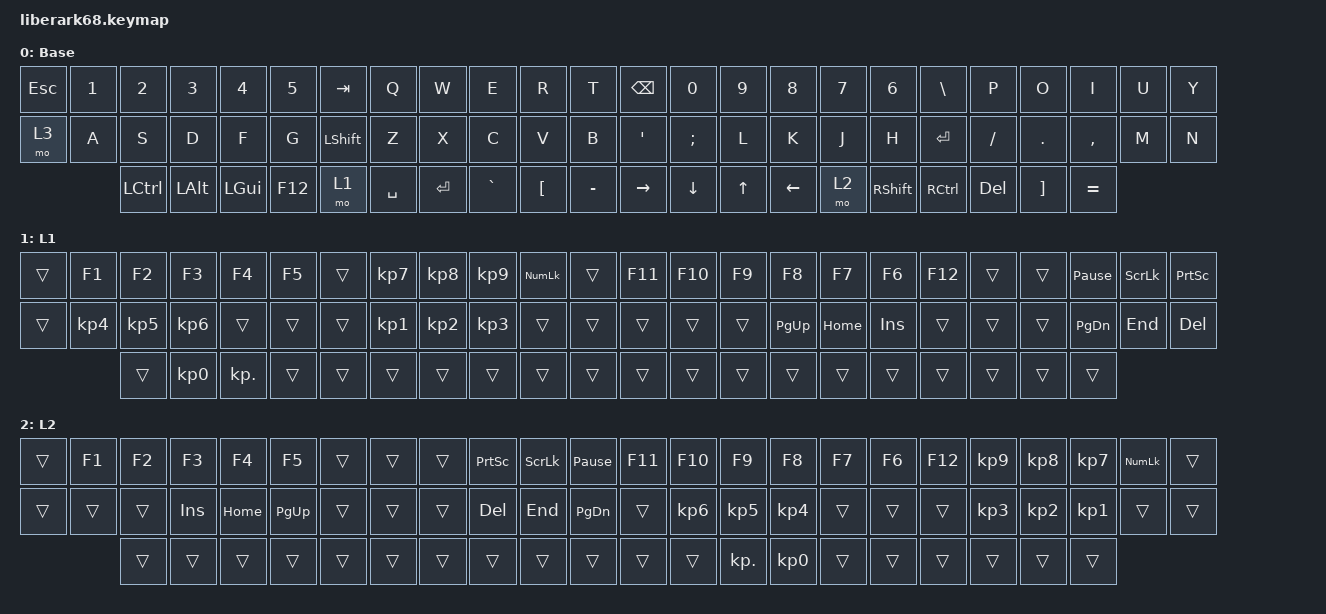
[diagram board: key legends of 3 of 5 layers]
/*
 * LiberArk68 default keymap (dual-fader variant).
 *
 * Bindings order matches the matrix-transform map in liberark68.dtsi:
 *   row 0: L cols 0..11, then R cols 0..11   (24)
 *   row 1: L cols 0..11, then R cols 0..11   (24)
 *   row 2: L cols 0..9,  then R cols 0..9    (20)
 *
 * The faders are analog inputs (not keys), so they don't appear here.
 * Momentary layer keys from the KLE: L outer-mid -> mo 3, L thumb -> mo 1,
 * R thumb -> mo 2. Layers 1 and 2 provide mirrored keypad/navigation layouts;
 * layers 3 and 4 remain placeholder &trans maps.
 */

#include <behaviors.dtsi>
#include <dt-bindings/zmk/keys.h>
#include <dt-bindings/zmk/bt.h>

#define TRANS_ROW_24 \
&trans &trans &trans &trans &trans &trans &trans &trans &trans &trans &trans &trans \
&trans &trans &trans &trans &trans &trans &trans &trans &trans &trans &trans &trans

#define TRANS_ROW_20 \
&trans &trans &trans &trans &trans &trans &trans &trans &trans &trans \
&trans &trans &trans &trans &trans &trans &trans &trans &trans &trans

/ {
    keymap {
        compatible = "zmk,keymap";

        default_layer {
            display-name = "Base";
            bindings = <
/* row 0  L0..L11                                                                                       R0..R11                                                                                  */
&kp ESC   &kp N1  &kp N2    &kp N3   &kp N4    &kp N5    &kp TAB    &kp Q  &kp W  &kp E  &kp R  &kp T   &kp BSPC   &kp N0  &kp N9    &kp N8   &kp N7  &kp N6   &kp BSLH   &kp P  &kp O  &kp I  &kp U  &kp Y

/* row 1                                                                                                                                                                                          */
&mo 3    &kp A   &kp S     &kp D    &kp F     &kp G    &kp LSHFT  &kp Z  &kp X  &kp C  &kp V  &kp B    &kp SQT    &kp SEMI &kp L  &kp K  &kp J  &kp H  &kp RET    &kp FSLH  &kp DOT &kp COMMA &kp M &kp N

/* row 2  L0..L9                                                                              R0..R9                                                                                              */
&kp LCTRL &kp LALT &kp LGUI &kp F12  &mo 1     &kp SPACE &kp RET    &kp GRAVE &kp LBKT &kp MINUS    &kp RIGHT &kp DOWN &kp UP &kp LEFT &mo 2 &kp RSHFT &kp RCTRL &kp DEL  &kp RBKT  &kp EQUAL
            >;
        };

        layer_1 {
            display-name = "L1";
            bindings = <
/* row 0  L0..L11                                                                                                                     R0..R11                                                                                             */
&trans &kp F1 &kp F2 &kp F3 &kp F4 &kp F5  &trans &kp KP_N7 &kp KP_N8 &kp KP_N9 &kp KP_NUMLOCK &trans    &kp F11 &kp F10 &kp F9 &kp F8 &kp F7 &kp F6  &kp F12 &trans &trans &kp PAUSE_BREAK &kp SLCK &kp PSCRN

/* row 1                                                                                                                                                                                                                             */
&trans &kp KP_N4 &kp KP_N5 &kp KP_N6 &trans &trans  &trans &kp KP_N1 &kp KP_N2 &kp KP_N3 &trans &trans    &trans &trans &trans &kp PG_UP &kp HOME &kp INSERT  &trans &trans &trans &kp PG_DN &kp END &kp DEL

/* row 2  L0..L9                                                                                                      R0..R9                                                                                                         */
&trans &kp KP_N0 &kp KP_DOT &trans &trans &trans &trans &trans &trans &trans    &trans &trans &trans &trans &trans &trans &trans &trans &trans &trans
            >;
        };

        layer_2 {
            display-name = "L2";
            bindings = <
/* row 0  L0..L11                                                                                               R0..R11                                                                                                                   */
&trans &kp F1 &kp F2 &kp F3 &kp F4 &kp F5  &trans &trans &trans &kp PSCRN &kp SLCK &kp PAUSE_BREAK    &kp F11 &kp F10 &kp F9 &kp F8 &kp F7 &kp F6  &kp F12 &kp KP_N9 &kp KP_N8 &kp KP_N7 &kp KP_NUMLOCK &trans

/* row 1                                                                                                                                                                                                                                  */
&trans &trans &trans &kp INSERT &kp HOME &kp PG_UP  &trans &trans &trans &kp DEL &kp END &kp PG_DN    &trans &kp KP_N6 &kp KP_N5 &kp KP_N4 &trans &trans  &trans &kp KP_N3 &kp KP_N2 &kp KP_N1 &trans &trans

/* row 2  L0..L9                                                                                         R0..R9                                                                                                                            */
&trans &trans &trans &trans &trans &trans &trans &trans &trans &trans    &trans &trans &kp KP_DOT &kp KP_N0 &trans &trans &trans &trans &trans &trans
            >;
        };

        layer_3 {
            display-name = "L3";
            bindings = <
                TRANS_ROW_24
                TRANS_ROW_24
                TRANS_ROW_20
            >;
        };

        layer_4 {
            display-name = "L4";
            bindings = <
                TRANS_ROW_24
                TRANS_ROW_24
                TRANS_ROW_20
            >;
        };
    };
};
